# TOP_CTRL_TOP_CTRL register map
Vendor: Texas Instruments
Peripheral module from a debugger description file (folder AM263).
Registers are 32-bit, read-only, reset 0x0 unless marked. A register's access mark holds for its fields unless they carry their own. Offsets are as the file gives them; lines under a group give offsets from that group; [hi:lo] are bit positions; {n}, {i} and the like mark numbered series; 'fields as' and 'values as' point back to an identical list; <NAME> marks a mode.

## TOP_CTRL_TOP_CTRL
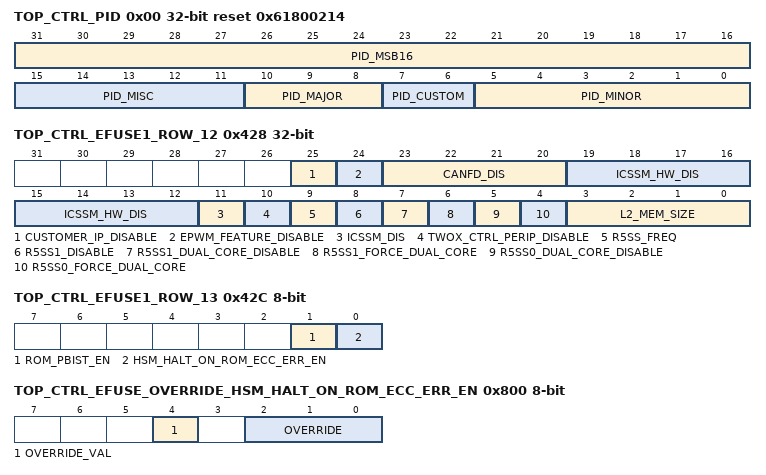
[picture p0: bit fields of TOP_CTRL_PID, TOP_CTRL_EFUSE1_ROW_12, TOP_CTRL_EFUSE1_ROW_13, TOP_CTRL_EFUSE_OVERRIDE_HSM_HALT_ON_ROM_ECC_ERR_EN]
0x00 TOP_CTRL_PID reset 0x61800214
  [31:16] PID_MSB16 — Not Defined
  [15:11] PID_MISC — Not Defined
  [10:8] PID_MAJOR — Not Defined
  [7:6] PID_CUSTOM — Not Defined
  [5:0] PID_MINOR — Not Defined
{0x10+4i} TOP_CTRL_EFUSE_DIEID{i} (i=0..3)
  [31:0] VAL — EFUSE DieID[{32i+31}:{32i}]
{0x20+4i} TOP_CTRL_EFUSE_UID{i} (i=0..2)
  [31:0] VAL — EFUSE UID[{32i+31}:{32i}]
0x2C TOP_CTRL_EFUSE_UID3 24-bit
  [23:0] VAL — EFUSE UID[120:96]
0x30 TOP_CTRL_EFUSE_DEVICE_TYPE 16-bit
  [15:0] VAL — EFUSE Device Type
0x34 TOP_CTRL_EFUSE_FROM0_CHECKSUM
  [31:0] VAL — 32 bit FROM0 Checksum
0x38 TOP_CTRL_EFUSE_JTAG_USERCODE_ID
  [31:0] VAL — EFUSE JTAG_USER_CODE_ID[31:0];. Denotes part variant
{0x30C+4i} TOP_CTRL_EFUSE0_ROW_{i} (i=61..63)
  [25:0] EFUSE0_ROW_{i} — Captures the EFUSE Value. Refer to EFUSE Mapping XLS for more details
{0x3F8+4i} TOP_CTRL_EFUSE1_ROW_{i} (i=5..11)
  [25:0] EFUSE1_ROW_{i} — Captures the EFUSE Value. Refer to EFUSE Mapping XLS for more details
0x428 TOP_CTRL_EFUSE1_ROW_12
  [25] CUSTOMER_IP_DISABLE — Customer IP set control0 - All IPs enabled1 - Customer IP set disabled (PWM24-31,CMPSSA6-9,CMPSSB6-9 disabled)
  [24] EPWM_FEATURE_DISABLE — Customer protected features inside PWM IP 0 - All features enabled1 - Customer defined features are protected
  [23:20] CANFD_DIS — CANFD disables. Bit positions correspond to CAN instance. 0 - CAN is enabled1 - CAN is disabled
  [19:12] ICSSM_HW_DIS — See ICSSM Spec for features
  [11] ICSSM_DIS — ICSSM IP disable0 - ICSSM enabled1 - ICSSM disabled
  [10] TWOX_CTRL_PERIP_DISABLE — 2x control IPs enabled0 - 1x control IPs (refer to PRD for the IP counts)1 - 2x control IPs (refer to PRD for the IP counts)
  [9] R5SS_FREQ — R5SS Freq0 - 400 MHz1 - 200 MHz
  [8] R5SS1_DISABLE — R5SS1 Disabled
  [7] R5SS1_DUAL_CORE_DISABLE — Force Lock step
  [6] R5SS1_FORCE_DUAL_CORE — Force Dual core
  [5] R5SS0_DUAL_CORE_DISABLE — Force Lock step
  [4] R5SS0_FORCE_DUAL_CORE — Force Dual core
  [3:0] L2_MEM_SIZE — Captures the EFUSE Value. Refer to EFUSE Mapping XLS for more details
0x42C TOP_CTRL_EFUSE1_ROW_13 8-bit
  [1] ROM_PBIST_EN — ROM PBIST ENABLE C ONTROL0 - PBIST DISABLE1 - PBIST ENABLE
  [0] HSM_HALT_ON_ROM_ECC_ERR_EN — Enabling halting of the HSM operation on a ROM ECC error that is detected.
{0x3F8+4i} TOP_CTRL_EFUSE1_ROW_{i} (i=14..56)
  fields as TOP_CTRL_EFUSE1_ROW_5
0x500 TOP_CTRL_MAC_ID0
  [31:0] MACID_LO — MAC ID low [32bits]
0x504 TOP_CTRL_MAC_ID1 16-bit
  [15:0] MACID_HI — MAC ID high [16bits]
0x510 TOP_CTRL_TRIM_TEMP_M40C 16-bit
  [10:0] TEMP — Record the temperature at which the temp sensor trims were performed
0x514 TOP_CTRL_TRIM_TEMPSENSE_M40C0
  [31:0] TRIM — Trim for temperature sensor calibration [Lower 32bits]
0x518 TOP_CTRL_TRIM_TEMPSENSE_M40C1 8-bit
  [8:0] TRIM — Trim for temperature sensor calibration [Upper 9bits]
0x51C TOP_CTRL_TRIM_TEMP_150C 16-bit
  fields as TOP_CTRL_TRIM_TEMP_M40C
0x520 TOP_CTRL_TRIM_TEMPSENSE_150C0
  [31:0] TRIM — Trim for temperature sensor calibration [Lower 32bits]
0x524 TOP_CTRL_TRIM_TEMPSENSE_150C1 8-bit
  [8:0] TRIM — Trim for temperature sensor calibration [Upper 9bits]
0x528 TOP_CTRL_TRIM_TEMP_30C 16-bit
  fields as TOP_CTRL_TRIM_TEMP_M40C
0x52C TOP_CTRL_TRIM_TEMPSENSE_30C0
  [31:0] TRIM — Trim for temperature sensor calibration [Lower 32bits]
0x530 TOP_CTRL_TRIM_TEMPSENSE_30C1 8-bit
  [8:0] TRIM — Trim for temperature sensor calibration [Upper 9bits]
0x534 TOP_CTRL_N_FACTOR_TEMPSENSE 16-bit
  [13:0] VAL — Temp Sensor N factor
0x538 TOP_CTRL_TSHUT_HOT 8-bit
  [7:0] VAL — Default efuse defined hot temperature shutdown. Can be overriden by writing to TSENSE0_TSHUT
0x53C TOP_CTRL_TSHUT_COLD 8-bit
  [7:0] VAL — Default efuse defined cold temperature shutdown. Can be overriden by writing to TSENSE0_TSHUT
0x800 TOP_CTRL_EFUSE_OVERRIDE_HSM_HALT_ON_ROM_ECC_ERR_EN 8-bit rw
  [4] OVERRIDE_VAL — Override MMR value
  [2:0] OVERRIDE — Override EFUSE Value with SW ValueWrite 3'b000 : EFUSE ValueWrite 3'b111 : MMR Value
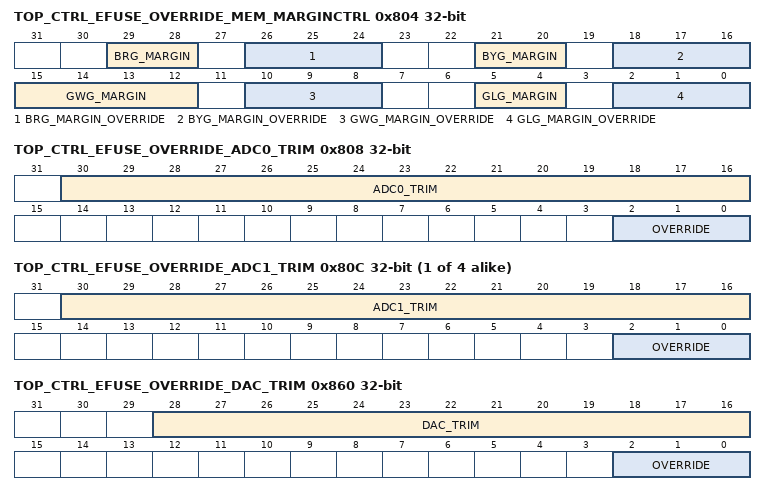
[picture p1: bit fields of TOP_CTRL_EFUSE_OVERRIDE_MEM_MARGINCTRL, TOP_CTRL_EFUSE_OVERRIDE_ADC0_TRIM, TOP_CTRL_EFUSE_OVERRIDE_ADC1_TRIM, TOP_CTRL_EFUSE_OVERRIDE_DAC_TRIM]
0x804 TOP_CTRL_EFUSE_OVERRIDE_MEM_MARGINCTRL rw
  [29:28] BRG_MARGIN — Override MMR value
  [26:24] BRG_MARGIN_OVERRIDE — Override EFUSE Value with SW ValueWrite 3'b000 : EFUSE ValueWrite 3'b111 : MMR Value
  [21:20] BYG_MARGIN — Override MMR value
  [18:16] BYG_MARGIN_OVERRIDE — Override EFUSE Value with SW ValueWrite 3'b000 : EFUSE ValueWrite 3'b111 : MMR Value
  [15:12] GWG_MARGIN — Override MMR value
  [10:8] GWG_MARGIN_OVERRIDE — Override EFUSE Value with SW ValueWrite 3'b000 : EFUSE ValueWrite 3'b111 : MMR Value
  [5:4] GLG_MARGIN — Override MMR value
  [2:0] GLG_MARGIN_OVERRIDE — Override EFUSE Value with SW ValueWrite 3'b000 : EFUSE ValueWrite 3'b111 : MMR Value
0x808 TOP_CTRL_EFUSE_OVERRIDE_ADC0_TRIM rw
  [30:16] ADC0_TRIM — offset trim of the ADC (3 values each 5 bit for SE-p, SE-m & Diff)
  [2:0] OVERRIDE — Override EFUSE Value with SW Value Write 3'b000 : EFUSE ValueWrite 3'b111 : MMR Value
{0x808+4i} TOP_CTRL_EFUSE_OVERRIDE_ADC{i}_TRIM rw (i=1..4)
  [30:16] ADC{i}_TRIM — offset trim of the ADC (3 values each 5 bit for SE-p, SE-m & Diff)
  [2:0] OVERRIDE — Override EFUSE Value with SW ValueWrite 3'b000 : EFUSE ValueWrite 3'b111 : MMR Value
0x81C TOP_CTRL_EFUSE_OVERRIDE_ADC_CFG_CTRL 8-bit rw
  [2:0] OVERRIDE — Override EFUSE Value with SW ValueWrite 3'b000 : EFUSE ValueWrite 3'b111 : MMR Value
0x820 TOP_CTRL_EFUSE_OVERRIDE_ADC_CFG0 rw reset 0x514554C9
  [31:0] ADC_CFG_31_0 — Family Trim. Will be same for all ADC's. Finalized during Bench/ATE char
0x824 TOP_CTRL_EFUSE_OVERRIDE_ADC_CFG1 rw reset 0x355688
  [31:0] ADC_CFG_63_32 — Family Trim. Will be same for all ADC's. Finalized during Bench/ATE char
0x828 TOP_CTRL_EFUSE_OVERRIDE_ADC_CFG2 24-bit rw reset 0x400001
  [23:0] ADC_CFG_87_64 — Family Trim. Will be same for all ADC's. Finalized during Bench/ATE char
0x82C TOP_CTRL_EFUSE_OVERRIDE_CSS01_TRIM_CTRL 8-bit rw
  fields as TOP_CTRL_EFUSE_OVERRIDE_ADC_CFG_CTRL
0x830 TOP_CTRL_EFUSE_OVERRIDE_CSS01_TRIM rw
  [31:0] CSS01_TRIM — CSS Trim signal
0x834 TOP_CTRL_EFUSE_OVERRIDE_CSS23_TRIM_CTRL 8-bit rw
  fields as TOP_CTRL_EFUSE_OVERRIDE_ADC_CFG_CTRL
0x838 TOP_CTRL_EFUSE_OVERRIDE_CSS23_TRIM rw
  [31:0] CSS23_TRIM — CSS Trim signal
0x83C TOP_CTRL_EFUSE_OVERRIDE_CSS45_TRIM_CTRL 8-bit rw
  fields as TOP_CTRL_EFUSE_OVERRIDE_ADC_CFG_CTRL
0x840 TOP_CTRL_EFUSE_OVERRIDE_CSS45_TRIM rw
  [31:0] CSS45_TRIM — CSS Trim signal
0x844 TOP_CTRL_EFUSE_OVERRIDE_CSS67_TRIM_CTRL 8-bit rw
  fields as TOP_CTRL_EFUSE_OVERRIDE_ADC_CFG_CTRL
0x848 TOP_CTRL_EFUSE_OVERRIDE_CSS67_TRIM rw
  [31:0] CSS67_TRIM — CSS Trim signal
0x84C TOP_CTRL_EFUSE_OVERRIDE_CSS89_TRIM_CTRL 8-bit rw
  fields as TOP_CTRL_EFUSE_OVERRIDE_ADC_CFG_CTRL
0x850 TOP_CTRL_EFUSE_OVERRIDE_CSS89_TRIM rw
  [31:0] CSS89_TRIM — CSS Trim signal
0x854 TOP_CTRL_EFUSE_OVERRIDE_CSS_CFG_CTRL 8-bit rw
  fields as TOP_CTRL_EFUSE_OVERRIDE_ADC_CFG_CTRL
0x858 TOP_CTRL_EFUSE_OVERRIDE_CSS_CFG0 rw
  [31:0] CSS_CFG_31_0 — Compdac Family trim (all CMPSS a & b)
0x85C TOP_CTRL_EFUSE_OVERRIDE_CSS_CFG1 rw
  [31:0] CSS_CFG_0_63_32 — Compdac Family trim (all CMPSS a & b)
0x860 TOP_CTRL_EFUSE_OVERRIDE_DAC_TRIM rw
  [28:16] DAC_TRIM — DAC Trim28:24 : [12:8] gain trim; 23:16 : [7:0] offset trim
  [2:0] OVERRIDE — Override EFUSE Value with SW ValueWrite 3'b000 : EFUSE ValueWrite 3'b111 : MMR Value
0x864 TOP_CTRL_EFUSE_OVERRIDE_DAC_CFG 24-bit rw
  [24] ASYNC_MODE_EN
  [17:16] IBIAS_CFG — ibias_cfg[1:0]
  [2:0] OVERRIDE — Override EFUSE Value with SW ValueWrite 3'b000 : EFUSE ValueWrite 3'b111 : MMR Value
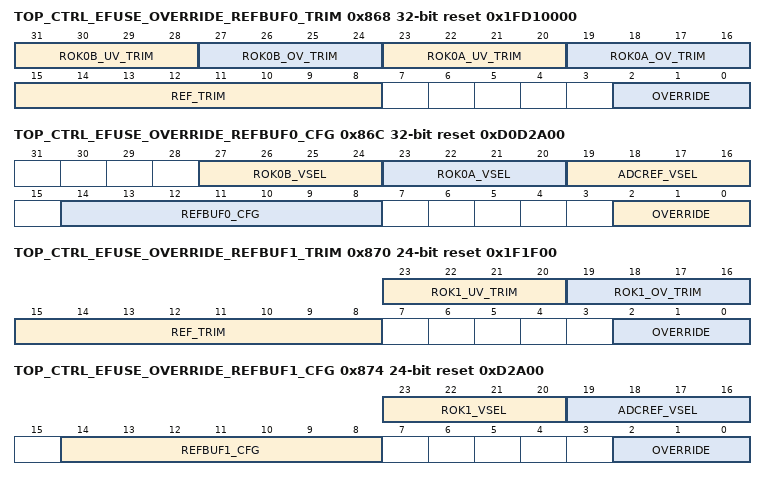
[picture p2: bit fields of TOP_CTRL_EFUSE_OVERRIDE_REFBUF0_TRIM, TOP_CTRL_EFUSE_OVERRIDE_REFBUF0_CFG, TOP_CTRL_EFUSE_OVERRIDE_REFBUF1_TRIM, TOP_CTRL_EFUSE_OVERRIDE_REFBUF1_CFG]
0x868 TOP_CTRL_EFUSE_OVERRIDE_REFBUF0_TRIM rw reset 0x1FD10000
  [31:28] ROK0B_UV_TRIM — ROK0B Under voltage threshold trim
  [27:24] ROK0B_OV_TRIM — ROK0B Over voltage threshold trim
  [23:20] ROK0A_UV_TRIM — ROK0A Under voltage threshold trim
  [19:16] ROK0A_OV_TRIM — ROK0A Over voltage threshold trim
  [15:8] REF_TRIM — Trims output voltage with 1mV steps, +/-30mV, default 0V
  [2:0] OVERRIDE — Override EFUSE Value with SW ValueWrite 3'b000 : EFUSE ValueWrite 3'b111 : MMR Value
0x86C TOP_CTRL_EFUSE_OVERRIDE_REFBUF0_CFG rw reset 0xD0D2A00
  [27:24] ROK0B_VSEL — Voltage selection for reference OK comp (1.46V to 1.86V) (ROK0B)
  [23:20] ROK0A_VSEL — Voltage selection for reference OK comp (1.46V to 1.86V)
  [19:16] ADCREF_VSEL — Selects output voltage level from 1.46V to 1.86V; default code is 1.8V
  [14:8] REFBUF0_CFG — Bit0: Debug feature, doubles the current of the 2nd stage. enfbres_pwdBit6-1: adjust current bias for the 1st, 2nd and 3rd stages.trim_ampbias[5:0]
  [2:0] OVERRIDE — Override EFUSE Value with SW ValueWrite 3'b000 : EFUSE ValueWrite 3'b111 : MMR Value
0x870 TOP_CTRL_EFUSE_OVERRIDE_REFBUF1_TRIM 24-bit rw reset 0x1F1F00
  [23:20] ROK1_UV_TRIM — ROK0A Under voltage threshold trim
  [19:16] ROK1_OV_TRIM — ROK0A Over voltage threshold trim
  [15:8] REF_TRIM — Trims output voltage with 1mV steps, +/-30mV, default 0V
  [2:0] OVERRIDE — Override EFUSE Value with SW ValueWrite 3'b000 : EFUSE ValueWrite 3'b111 : MMR Value
0x874 TOP_CTRL_EFUSE_OVERRIDE_REFBUF1_CFG 24-bit rw reset 0xD2A00
  [23:20] ROK1_VSEL — Voltage selection for reference OK comp (1.46V to 1.86V)
  [19:16] ADCREF_VSEL — Selects output voltage level from 1.46V to 1.86V; default code is 1.8V
  [14:8] REFBUF1_CFG — Bit0: Debug feature, doubles the current of the 2nd stage. enfbres_pwdBit6-1: adjust current bias for the 1st, 2nd and 3rd stages.trim_ampbias[5:0]
  [2:0] OVERRIDE — Override EFUSE Value with SW ValueWrite 3'b000 : EFUSE ValueWrite 3'b111 : MMR Value
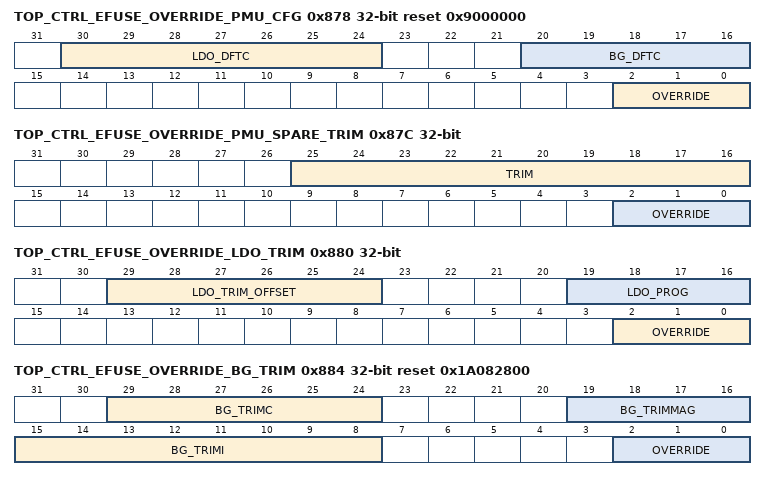
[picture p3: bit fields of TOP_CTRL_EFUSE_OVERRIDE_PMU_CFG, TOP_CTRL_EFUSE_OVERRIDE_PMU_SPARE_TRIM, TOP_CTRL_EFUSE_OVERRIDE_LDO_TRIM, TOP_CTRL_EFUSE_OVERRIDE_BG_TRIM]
0x878 TOP_CTRL_EFUSE_OVERRIDE_PMU_CFG rw reset 0x9000000
  [30:24] LDO_DFTC — Main LDO(1.8v) Config signals.Bit15: Not UsedBit14: 1 Double current in clampBit13: 1 Local ~200uA load resistor connected to ldooutBit12: 1 Amplifier ok bypassedBit 11-10: Adjust master current mirror in amplifier 2'b11 = 0.67x current 2'b10 = 0.5x current 2'b01 = 2.0x current 2'b00 = 1.0x currentBit9: 1 Allows higher slewing current (should only assert after bootup)
  [20:16] BG_DFTC — Bandgap DFT controls for debug purposes.Bit7: 1 To short large BJT base resistor to GNDBit6: 1 To short small BJT base resistor to GNDBit5: 1 To turn OFF startup pull NMOSBit4: 1 To turn OFF startup currentBit3: 1 to adjust(increase) BGAMP biasing
  [2:0] OVERRIDE — Override EFUSE Value with SW ValueWrite 3'b000 : EFUSE ValueWrite 3'b111 : MMR Value
0x87C TOP_CTRL_EFUSE_OVERRIDE_PMU_SPARE_TRIM rw
  [25:16] TRIM — PMU spare trim override value{pmu_trim_1p1v<7:6>,pmu_trim_1p1v<19:18>,pmu_trim_1p1v<35:30>}
  [2:0] OVERRIDE — Override EFUSE Value for PMU SPARE trimWrite 3'b000 : EFUSE ValueWrite 3'b111 : MMR Value
0x880 TOP_CTRL_EFUSE_OVERRIDE_LDO_TRIM rw
  [29:24] LDO_TRIM_OFFSET — LDO Fine trim around program point
  [19:16] LDO_PROG — LDO programming controls. Adjusts nominal LDO output voltage
  [2:0] OVERRIDE — Override EFUSE Value with SW ValueWrite 3'b000 : EFUSE ValueWrite 3'b111 : MMR Value
0x884 TOP_CTRL_EFUSE_OVERRIDE_BG_TRIM rw reset 0x1A082800
  [29:24] BG_TRIMC — Bandgap curvture/slope trim bits
  [19:16] BG_TRIMMAG — Bandgap magnitude trim bits
  [15:8] BG_TRIMI — [19:18] = Unused[17:12] = Bandgap current trim bits
  [2:0] OVERRIDE — Override EFUSE Value with SW ValueWrite 3'b000 : EFUSE ValueWrite 3'b111 : MMR Value
0x888 TOP_CTRL_EFUSE_OVERRIDE_SFTYMON_THRHLD_TRIM_CTRL 8-bit rw
  fields as TOP_CTRL_EFUSE_OVERRIDE_ADC_CFG_CTRL
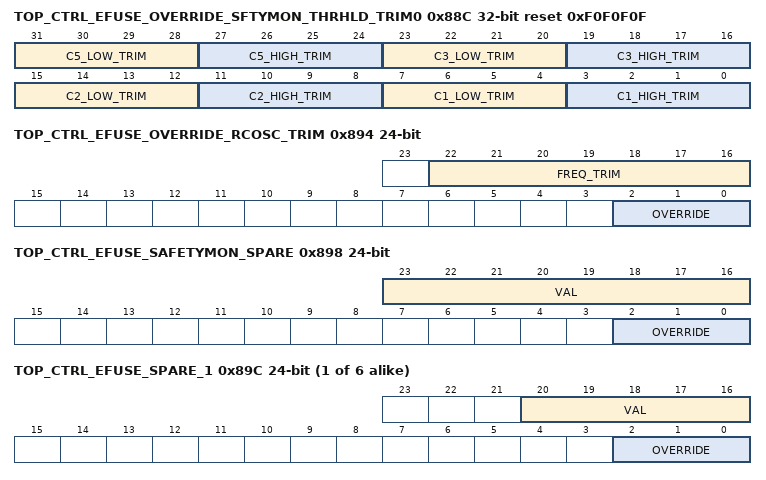
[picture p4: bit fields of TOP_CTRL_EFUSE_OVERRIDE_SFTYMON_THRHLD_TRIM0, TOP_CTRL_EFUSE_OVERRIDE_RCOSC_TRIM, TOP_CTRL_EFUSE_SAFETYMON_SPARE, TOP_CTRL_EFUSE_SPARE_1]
0x88C TOP_CTRL_EFUSE_OVERRIDE_SFTYMON_THRHLD_TRIM0 rw reset 0xF0F0F0F
  [31:28] C5_LOW_TRIM — C5, low side threshold trim setting
  [27:24] C5_HIGH_TRIM — C5, high side threshold trim setting
  [23:20] C3_LOW_TRIM — C3, low side threshold trim setting
  [19:16] C3_HIGH_TRIM — C3, high side threshold trim setting
  [15:12] C2_LOW_TRIM — C2, low side threshold trim setting
  [11:8] C2_HIGH_TRIM — C2, high side threshold trim setting
  [7:4] C1_LOW_TRIM — C1, low side threshold trim setting
  [3:0] C1_HIGH_TRIM — C1, high side threshold trim setting;
0x890 TOP_CTRL_EFUSE_OVERRIDE_SFTYMON_THRHLD_TRIM1 8-bit rw
  [3:0] C8_LOW_TRIM — C8, low side threshold trim setting
0x894 TOP_CTRL_EFUSE_OVERRIDE_RCOSC_TRIM 24-bit rw
  [22:16] FREQ_TRIM — RC oscillator frequency trim
  [2:0] OVERRIDE — Override EFUSE Value with SW ValueWrite 3'b000 : EFUSE ValueWrite 3'b111 : MMR Value
0x898 TOP_CTRL_EFUSE_SAFETYMON_SPARE 24-bit rw
  [23:16] VAL — SAFETYMON_SPARE trim override value
  [2:0] OVERRIDE — Override EFUSE Value with SW ValueWrite 3'b000 : EFUSE ValueWrite 3'b111 : MMR Value
{0x898+4i} TOP_CTRL_EFUSE_SPARE_{i} 24-bit rw (i=1..6)
  [20:16] VAL — SPARE_{i} trim override value
  [2:0] OVERRIDE — Override EFUSE Value with SW ValueWrite 3'b000 : EFUSE ValueWrite 3'b111 : MMR Value
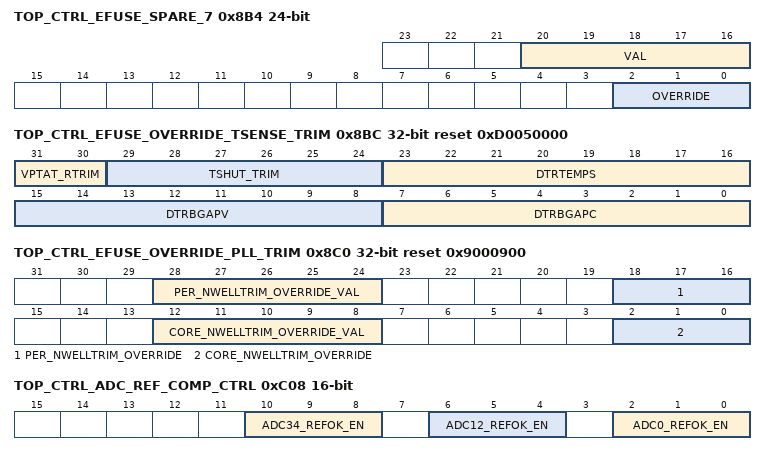
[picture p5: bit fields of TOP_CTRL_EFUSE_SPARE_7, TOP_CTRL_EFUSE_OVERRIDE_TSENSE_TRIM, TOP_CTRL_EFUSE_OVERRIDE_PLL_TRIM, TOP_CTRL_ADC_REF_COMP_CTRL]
0x8B4 TOP_CTRL_EFUSE_SPARE_7 24-bit rw
  [20:16] VAL — SPARE_6 trim override value
  [2:0] OVERRIDE — Override EFUSE Value with SW ValueWrite 3'b000 : EFUSE ValueWrite 3'b111 : MMR Value
0x8B8 TOP_CTRL_EFUSE_OVERRIDE_TSENSE_TRIM_CTRL 8-bit rw
  fields as TOP_CTRL_EFUSE_OVERRIDE_ADC_CFG_CTRL
0x8BC TOP_CTRL_EFUSE_OVERRIDE_TSENSE_TRIM rw reset 0xD0050000
  [31:30] VPTAT_RTRIM — TS: Vptat R trim (PTAT voltage resistor trim)
  [29:24] TSHUT_TRIM — Tshut Temperature C (Shutdown temperature trim)
  [23:16] DTRTEMPS — RDAC offset trim
  [15:8] DTRBGAPV — TS Bandgap magnitude trim
  [7:0] DTRBGAPC — TS Bandgap curvature trim
0x8C0 TOP_CTRL_EFUSE_OVERRIDE_PLL_TRIM rw reset 0x9000900
  [28:24] PER_NWELLTRIM_OVERRIDE_VAL — Peripheral ADPLL trim override value when per_adpll_trim_override is programmed
  [18:16] PER_NWELLTRIM_OVERRIDE — Peripheral ADPLL trim value is overridden by per_adpll_trim_override_val when this bit is programmed 1
  [12:8] CORE_NWELLTRIM_OVERRIDE_VAL — Core ADPLL trim override value when core_adpll_trim_override is programmed
  [2:0] CORE_NWELLTRIM_OVERRIDE — Core ADPLL trim value is overridden by core_adpll_trim_override_val when this bit is programmed 1
0xC00 TOP_CTRL_ADC_REFBUF0_CTRL 8-bit rw
  [2:0] ENABLE — Enables adc reference 0, mask hhv before enable000: Disable111 : Enable
0xC04 TOP_CTRL_ADC_REFBUF1_CTRL 8-bit rw
  fields as TOP_CTRL_ADC_REFBUF0_CTRL
0xC08 TOP_CTRL_ADC_REF_COMP_CTRL 16-bit rw
  [10:8] ADC34_REFOK_EN — enables reference comparators (ROK1). This monitors adc3 & adc4 refernc
  [6:4] ADC12_REFOK_EN — enables reference comparators (ROK0B). This monitors adc1 & adc2 refernce
  [2:0] ADC0_REFOK_EN — enables reference comparators (ROK0). This monitors adc0 refernce
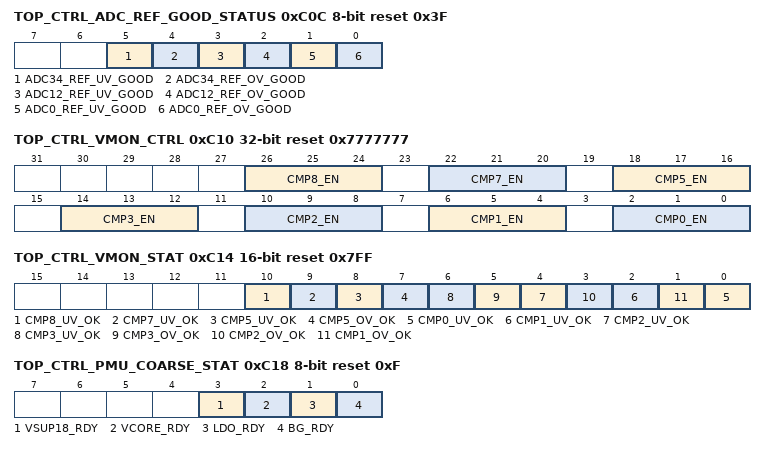
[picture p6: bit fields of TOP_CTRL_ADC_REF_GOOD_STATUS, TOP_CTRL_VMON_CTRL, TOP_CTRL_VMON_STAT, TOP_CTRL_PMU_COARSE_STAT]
0xC0C TOP_CTRL_ADC_REF_GOOD_STATUS 8-bit reset 0x3F
  [5] ADC34_REF_UV_GOOD — Under Voltage check OK
  [4] ADC34_REF_OV_GOOD — Over voltage check OK
  [3] ADC12_REF_UV_GOOD — Under Voltage check OK
  [2] ADC12_REF_OV_GOOD — Over voltage check OK
  [1] ADC0_REF_UV_GOOD — Under Voltage check OK
  [0] ADC0_REF_OV_GOOD — Over voltage check OK
0xC10 TOP_CTRL_VMON_CTRL rw reset 0x7777777
  [26:24] CMP8_EN — VMON EN
  [22:20] CMP7_EN — VMON EN
  [18:16] CMP5_EN — VMON EN
  [4n+2:4n] CMP{n}_EN (n=0..3) — VMON EN
0xC14 TOP_CTRL_VMON_STAT 16-bit reset 0x7FF
  [10] CMP8_UV_OK — VMON OK
  [9] CMP7_UV_OK — VMON OK
  [8] CMP5_UV_OK — VMON OK
  [7] CMP5_OV_OK — VMON OK
  [2n] CMP{n}_UV_OK (n=0..3) — VMON OK
  [5] CMP3_OV_OK — VMON OK
  [3] CMP2_OV_OK — VMON OK
  [1] CMP1_OV_OK — VMON OK
0xC18 TOP_CTRL_PMU_COARSE_STAT 8-bit reset 0xF
  [3] VSUP18_RDY — Coarse VMON OK
  [2] VCORE_RDY — Coarse VMON OK
  [1] LDO_RDY — Coarse VMON OK
  [0] BG_RDY — Coarse VMON OK
0xC20 TOP_CTRL_MASK_VMON_ERROR_ESM_H 16-bit rw reset 0x1FFFF
  [16] ADC34_REF_UV_MASK — VMON Error Mask to ESM
  [15] ADC34_REF_OV_MASK — VMON Error Mask to ESM
  [14] ADC12_REF_UV_MASK — VMON Error Mask to ESM
  [13] ADC12_REF_OV_MASK — VMON Error Mask to ESM
  [12] ADC0_REF_UV_MASK — VMON Error Mask to ESM
  [11] ADC0_REF_OV_MASK — VMON Error Mask to ESM
  [10] CMP8_UV_ERR_MASK — VMON Error Mask to ESM
  [9] CMP7_UV_ERR_MASK — VMON Error Mask to ESM
  [8] CMP5_UV_ERR_MASK — VMON Error Mask to ESM
  [7] CMP5_OV_ERR_MASK — VMON Error Mask to ESM
  [6] CMP3_UV_ERR_MASK — VMON Error Mask to ESM
  [5] CMP3_OV_ERR_MASK — VMON Error Mask to ESM
  [4] CMP2_UV_ERR_MASK — VMON Error Mask to ESM
  [3] CMP2_OV_ERR_MASK — VMON Error Mask to ESM
  [2] CMP1_UV_ERR_NASK — VMON Error Mask to ESM
  [1] CMP1_OV_ERR_MASK — VMON Error Mask to ESM
  [0] CMP0_UV_ERR_MASK — VMON Error Mask to ESM
0xC24 TOP_CTRL_MASK_VMON_ERROR_ESM_L 16-bit rw reset 0x1FFFF
  [16] ADC34_REF_UV_MASK — VMON Error Mask to INTR
  [15] ADC34_REF_OV_MASK — VMON Error Mask to INTR
  [14] ADC12_REF_UV_MASK — VMON Error Mask to INTR
  [13] ADC12_REF_OV_MASK — VMON Error Mask to INTR
  [12] ADC0_REF_UV_MASK — VMON Error Mask to INTR
  [11] ADC0_REF_OV_MASK — VMON Error Mask to INTR
  [10] CMP8_UV_ERR_MASK — VMON Error Mask to INTR
  [9] CMP7_UV_ERR_MASK — VMON Error Mask to INTR
  [8] CMP5_UV_ERR_MASK — VMON Error Mask to INTR
  [7] CMP5_OV_ERR_MASK — VMON Error Mask to INTR
  [6] CMP3_UV_ERR_MASK — VMON Error Mask to INTR
  [5] CMP3_OV_ERR_MASK — VMON Error Mask to INTR
  [4] CMP2_UV_ERR_MASK — VMON Error Mask to INTR
  [3] CMP2_OV_ERR_MASK — VMON Error Mask to INTR
  [2] CMP1_UV_ERR_NASK — VMON Error Mask to INTR
  [1] CMP1_OV_ERR_MASK — VMON Error Mask to INTR
  [0] CMP0_UV_ERR_MASK — VMON Error Mask to INTR
0xC30 TOP_CTRL_MASK_ANA_ISO 8-bit rw
  [2:0] MASK — Mask the Ana ISO generating SOC reset due to a glitch on VDD OK.Used during Trim updates to the analog or during ADC Refbuf enable
0xC34 TOP_CTRL_VMON_FILTER_CTRL 8-bit rw
  [1:0] SELECT_VALUE — VMON FILTER control select00 : no filtering (default)01 : filtering for 4.8us10 : filtering for 9.6us11 : filtering for 14.4us
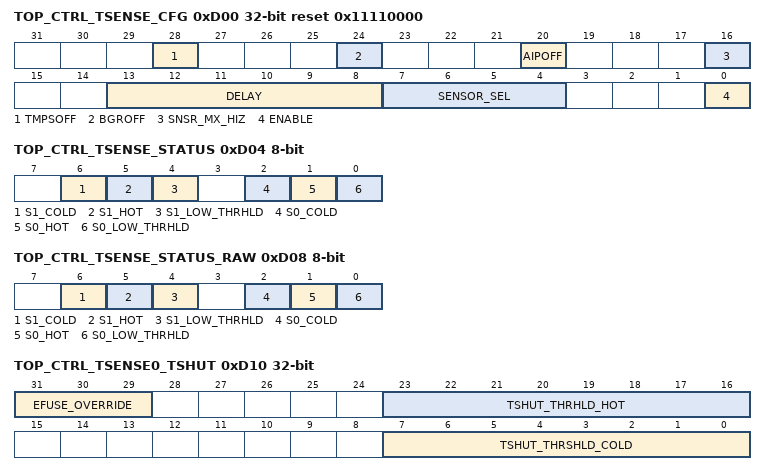
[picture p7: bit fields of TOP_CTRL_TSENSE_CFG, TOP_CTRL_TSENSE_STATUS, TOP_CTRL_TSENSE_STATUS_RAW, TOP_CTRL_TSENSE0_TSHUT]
0xD00 TOP_CTRL_TSENSE_CFG rw reset 0x11110000
  [28] TMPSOFF — Temperature sensor off0 : on1 : off
  [24] BGROFF — BandGap on/off control 1 : off 0 : on
  [20] AIPOFF — 1 : iddq mode select 0 : normal mode
  [16] SNSR_MX_HIZ — sensor mux hiz control0 : normal operation. Mux will select either one of the anlaog sensor 1 : mux will be high impedence
  [13:8] DELAY — number of wait clock cycles between each TMPS Readout. Configure a Non zero value as delay value since configuring 0 is not allowed
  [7:4] SENSOR_SEL — Sensor Selection sensor enable bits for each sensor 0 : sensor disable 1 : sensor enablebit 3: temp_sensor3bit 2: temp_sensor2bit 1: temp_sensor1bit 0: temp_sensor0
  [0] ENABLE — Temperature controller enable
0xD04 TOP_CTRL_TSENSE_STATUS 8-bit
  [6] S1_COLD — temperature Sensor 1 cold event detect0 : event not occured1 : event occurred
  [5] S1_HOT — temperature Sensor 1 hot event detect0 : event not occured1 : event occurred
  [4] S1_LOW_THRHLD — temperature Sensor 1 low threshold event detect0 : event not occured1 : event occurred
  [2] S0_COLD — temperature Sensor 0 cold event detect0 : event not occured1 : event occurred
  [1] S0_HOT — temperature Sensor 0 hot event detect0 : event not occured1 : event occurred
  [0] S0_LOW_THRHLD — temperature Sensor 0 low threshold event detect0 : event not occured1 : event occurred
0xD08 TOP_CTRL_TSENSE_STATUS_RAW 8-bit
  fields as TOP_CTRL_TSENSE_STATUS
0xD10 TOP_CTRL_TSENSE0_TSHUT rw
  [31:29] EFUSE_OVERRIDE — Efuse override000 -- Value from EFUSE is used as tshut hot and tshut cold thresholds111 - Overide value takes effect
  [23:16] TSHUT_THRHLD_HOT — tshut hot threshold. Reads efuse value untill overwritten with override = 111
  [7:0] TSHUT_THRSHLD_COLD — tshut cold threshold. Reads efuse value untill overwritten with override = 111
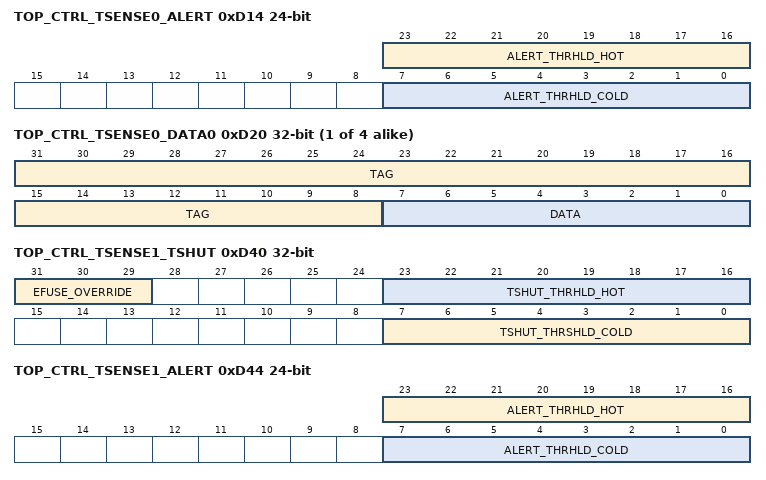
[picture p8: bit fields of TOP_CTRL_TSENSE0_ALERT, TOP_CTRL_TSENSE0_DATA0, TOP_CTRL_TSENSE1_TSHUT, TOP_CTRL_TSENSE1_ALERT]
0xD14 TOP_CTRL_TSENSE0_ALERT 24-bit rw
  [23:16] ALERT_THRHLD_HOT — hot threshold/high temp threshold
  [7:0] ALERT_THRHLD_COLD — cold threshold/low temp threshold
0xD18 TOP_CTRL_TSENSE0_CNTL 24-bit rw reset 0x100000
  [24] MASK_LOW_THRHLD — mask low threshold comparator output
  [20] MASK_COLD — mask cold comparator output
  [16] MASK_HOT — Mask hot comparator output
  [8] ACCU_CLEAR — accumulator clear
  [4] FIFO_FREEZE
  [0] FIFO_CLEAR
{0xD1C+0x30*i} TOP_CTRL_TSENSE{i}_RESULT 16-bit (i=0..3)
  [16] ECOZ — Conversion in Progress.1 : Conversion on going0 : conversion completed
  [7:0] DTEMP — Temp Code readout
{0xD20+4i} TOP_CTRL_TSENSE0_DATA{i} (i=0..3)
  [31:8] TAG — tag {i}
  [7:0] DATA — fifo data {i}
0xD30 TOP_CTRL_TSENSE0_ACCU
  [31:0] CUMUL — cumulative sum of past DTEMPs
0xD40 TOP_CTRL_TSENSE1_TSHUT rw
  fields as TOP_CTRL_TSENSE0_TSHUT
0xD44 TOP_CTRL_TSENSE1_ALERT 24-bit rw
  fields as TOP_CTRL_TSENSE0_ALERT
0xD48 TOP_CTRL_TSENSE1_CNTL 24-bit rw reset 0x100000
  fields as TOP_CTRL_TSENSE0_CNTL
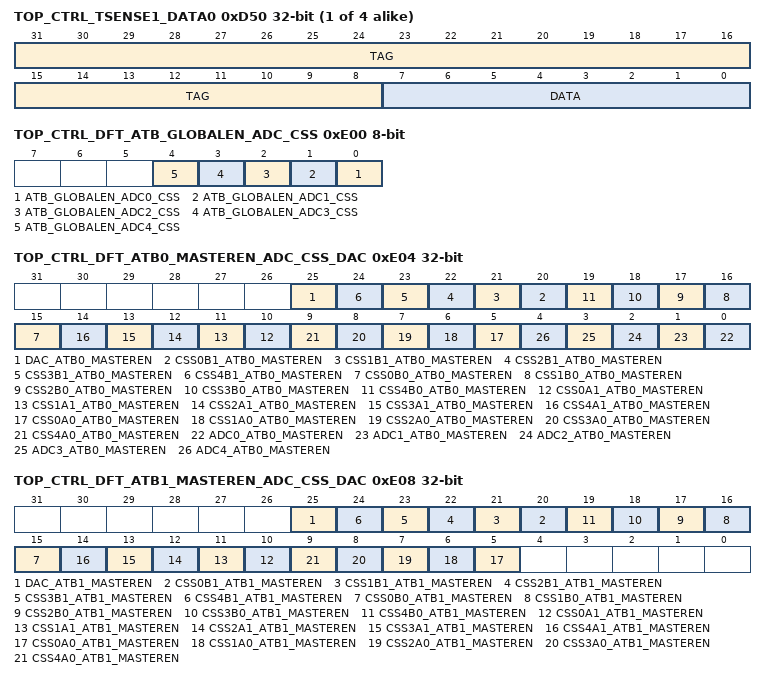
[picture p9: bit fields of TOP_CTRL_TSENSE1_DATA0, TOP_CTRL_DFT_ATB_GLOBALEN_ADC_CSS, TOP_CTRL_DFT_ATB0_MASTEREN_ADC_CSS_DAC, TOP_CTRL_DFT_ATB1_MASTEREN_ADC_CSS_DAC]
{0xD50+4i} TOP_CTRL_TSENSE1_DATA{i} (i=0..3)
  [31:8] TAG — tag {i}
  [7:0] DATA — fifo data {i}
0xD60 TOP_CTRL_TSENSE1_ACCU
  [31:0] CUMUL — cumulative sum of past DTEMPs
0xE00 TOP_CTRL_DFT_ATB_GLOBALEN_ADC_CSS 8-bit rw
  [n] ATB_GLOBALEN_ADC{n}_CSS (n=0..4) — ADC does not use 3V ATB This signal is used to enable master 3V & 1.8V switch (gates all cmpss 3V ATB access and cmpss+adc 1.8V atb access)
0xE04 TOP_CTRL_DFT_ATB0_MASTEREN_ADC_CSS_DAC rw
  [25] DAC_ATB0_MASTEREN — Master Enable : atb0 of dac12
  [n+20] CSS{n}B1_ATB0_MASTEREN (n=0..4) — Master Enable : atb0 of corresponding subsystems cmpss-b1
  [n+15] CSS{n}B0_ATB0_MASTEREN (n=0..4) — Master Enable : atb0 of corresponding subsystems cmpss-b0
  [n+10] CSS{n}A1_ATB0_MASTEREN (n=0..4) — Master Enable : atb0 of corresponding subsystems cmpss-a1
  [n+5] CSS{n}A0_ATB0_MASTEREN (n=0..4) — Master Enable : atb0 of corresponding subsystems cmpss-a0
  [n] ADC{n}_ATB0_MASTEREN (n=0..4) — Master Enable : atb0 of corresponding adc
0xE08 TOP_CTRL_DFT_ATB1_MASTEREN_ADC_CSS_DAC rw
  [25] DAC_ATB1_MASTEREN — Master Enable : atb0 of dac12
  [n+20] CSS{n}B1_ATB1_MASTEREN (n=0..4) — Master Enable : atb0 of corresponding subsystems cmpss-b1
  [n+15] CSS{n}B0_ATB1_MASTEREN (n=0..4) — Master Enable : atb0 of corresponding subsystems cmpss-b0
  [n+10] CSS{n}A1_ATB1_MASTEREN (n=0..4) — Master Enable : atb0 of corresponding subsystems cmpss-a1
  [n+5] CSS{n}A0_ATB1_MASTEREN (n=0..4) — Master Enable : atb0 of corresponding subsystems cmpss-a0
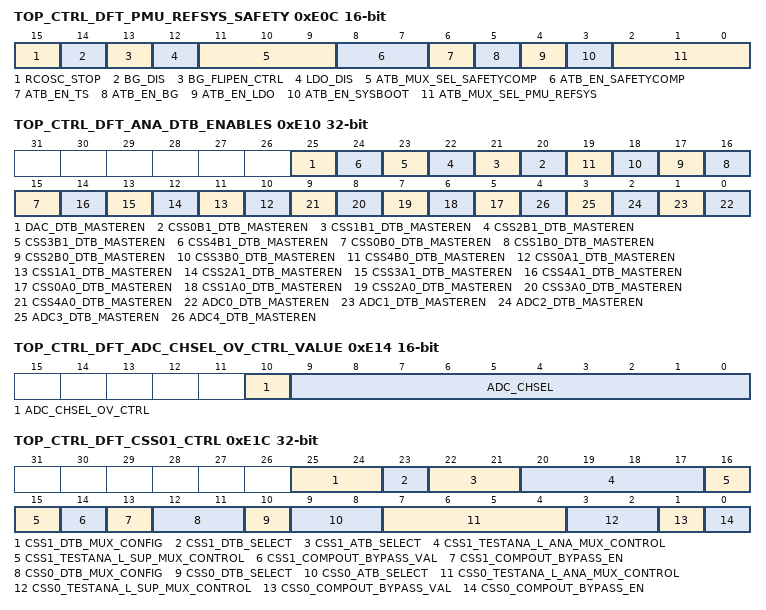
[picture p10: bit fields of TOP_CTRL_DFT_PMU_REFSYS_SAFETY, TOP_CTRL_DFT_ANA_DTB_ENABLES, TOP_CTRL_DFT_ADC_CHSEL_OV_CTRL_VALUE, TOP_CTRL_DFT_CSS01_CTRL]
0xE0C TOP_CTRL_DFT_PMU_REFSYS_SAFETY 16-bit rw
  [15] RCOSC_STOP — 0:rc enabled 1: stops rcosc clock
  [14] BG_DIS — Bandgap disable signal.1'b0 = Bandgap enabled. 1'b1 = Badgap disabled
  [13] BG_FLIPEN_CTRL — Bandgap flipen control for amplifier offset correction during trimming.1'b0 => normal operation; 1'b1 => AMP inputs flipped.
  [12] LDO_DIS — Disables LDO if set '1'
  [11:9] ATB_MUX_SEL_SAFETYCOMP — Selects analog signals for atestoutput for each of the test modes of the safety comparators according to test mode controlled by tb_ctrl_1p1v<83:82> : Test Mode 1 (tb_ctrl_1p1v<83:82>='b01): C5 & C20: HIZ 1: vssa of C5; 2:vth_lo of C5; 3: vth_hi of C5; 4:vssa of C2;5:vth_lo of C2; 6: vth_hi of C2; 7:HIZTest Mode 2 (tb_ctrl_1p1v<83:82>='b10): C3 & C80: HIZ 1: vssa of C3; 2:vth_lo of C3; 3: vth_hi of C3; 4:vssa of C8;5:vth_lo of C8; 6: vref of C8 (1.2V*0.5); 7:HIZTest Mode 3 (tb_ctrl_1p1v<83:82>='b11): C1 & C00: HIZ 1: vssa of C1; 2:vth_lo of C1; 3: vth_hi of C1; 4:vssa of C0;5:vmon of C0; 6: vref of C0 ; 7:HIZSelects Analog Test Signals for Temperature Sensor if tb_ctrl_1p1v<81> is enabled (refer to the spec for details).
  [8:7] ATB_EN_SAFETYCOMP — Enables three different test modes for safety comparators: 00: HIZ01: Test Mode1 enable10: Test Mode 2 enable11: Test Mode 3 enable
  [6] ATB_EN_TS — Analog test mode enable for temperature sesnsor
  [5] ATB_EN_BG — Bandgap atest enabled
  [4] ATB_EN_LDO — LDO atest enabled.
  [3] ATB_EN_SYSBOOT — atest enable pins for PMU. Only one bit should be high at a time.system boot logic atest enabled.
  [2:0] ATB_MUX_SEL_PMU_REFSYS — Common atest channel selection bits for bandgap, sysboot and LDO.Decoded to enable 8 channels of each module.
0xE10 TOP_CTRL_DFT_ANA_DTB_ENABLES rw
  [25] DAC_DTB_MASTEREN — Master Enable : dtb0 of dac12
  [n+20] CSS{n}B1_DTB_MASTEREN (n=0..4) — Master Enable : dtb0 of corresponding subsystems cmpss-b1
  [n+15] CSS{n}B0_DTB_MASTEREN (n=0..4) — Master Enable : dtb0 of corresponding subsystems cmpss-b0
  [n+10] CSS{n}A1_DTB_MASTEREN (n=0..4) — Master Enable : dtb0 of corresponding subsystems cmpss-a1
  [n+5] CSS{n}A0_DTB_MASTEREN (n=0..4) — Master Enable : dtb0 of corresponding subsystems cmpss-a0
  [n] ADC{n}_DTB_MASTEREN (n=0..4) — Master Enable : dtb0 of corresponding adc
0xE14 TOP_CTRL_DFT_ADC_CHSEL_OV_CTRL_VALUE 16-bit rw
  [10] ADC_CHSEL_OV_CTRL — 1 bit as the override control
  [9:0] ADC_CHSEL — ADC Channel select overrides adcX_ctrl_1p1v signal
0xE18 TOP_CTRL_DFT_DAC_CTRL 8-bit rw
  [8] DFT_LOAD_HIGH_EN — Connects 5k resistor between Vout and vdd_3p3v
  [7] DFT_LOAD_LOW_EN — Connects 5k resistor between Vout and VSS
  [6] IBIAS_20UA_ATB — connects ibias_20uA current sink to test bus
  [5] RDAC_VREF_HI_ATB — Connects RDAC VREF_HI to test bus
  [4] RDAC_VREF_LOW_ATB — Connects RDAC VREF_LOW to test bus
  [3] VSS_ATB — Connects VSS to test bus
  [2] VFEEDBACK_ATB — Connects Vfeedback node to test bus
  [1] RDAC_VBOT_ATB — Connects RDAC VBOT node to test bus
  [0] RDAC_VTOP_ATB — Connects RDAC VTOP node to test bus
0xE1C TOP_CTRL_DFT_CSS01_CTRL rw
  [25:24] CSS1_DTB_MUX_CONFIG — 2 b00 = MSB (default)2 b01 = LSB2 b10 = Enable2 b11 = compout
  [23] CSS1_DTB_SELECT — 1 b0 = dtb connected for compL (default)1 b1 = dtb connected for compH
  [22:21] CSS1_ATB_SELECT — 2 b00 = atb off (default)2 b01 = atb enable for compL2 b10 = atb enable for compH2 b11 = both ATB active
  [20:17] CSS1_TESTANA_L_ANA_MUX_CONTROL — 4 b0000 = 1p8v testana isolated (default)4 b0001 = vref_int4 b0010 = vref_low4 b0011 = vdac<0>4 b0100 = vdac<1>4 b0101 = vss4 b0110 = ibias 10uA ( atleast 1.25v at the pad)4 b0111 = por_ibias 10uA (atleast 1.25v at the pad)4 b1000 = cmp out1_p4 b1001 = cmp_out1_n
  [16:15] CSS1_TESTANA_L_SUP_MUX_CONTROL — For: compssa_L POS IN // NEG IN2 b00 = POS Mux control // DAC (default)2 b01 = ATB // DAC (tb_ctrl_1p1v<1> = 1'b1)2 b10 = POS Mux control // ATB (tb_ctrl_1p1v<1> = 1'b1)2 b11 = POS Mux control // DAC - ATB shorted (tb_ctrl_1p1v<1> = 1'b1)For: compssa_H POS IN // NEG IN2 b00 = inh // NEG Mux control (default)2 b01 = ATB (tb_ctrl_1p1v<1> = 1'b1) // NEG Mux control2 b10 = inh // ATB (tb_ctrl_1p1v<1> = 1'b1)2 b11 = inh // DAC - ATB shorted (tb_ctrl_1p1v<1> = 1'b1)
  [14] CSS1_COMPOUT_BYPASS_VAL — comparator bypass value
  [13] CSS1_COMPOUT_BYPASS_EN — 1 b0 = compout is connected to internal comparator (default)1 b1 = compout is equal to compout_bypass_val
  [12:11] CSS0_DTB_MUX_CONFIG — 2 b00 = MSB (default)2 b01 = LSB2 b10 = Enable2 b11 = compout
  [10] CSS0_DTB_SELECT — 1 b0 = dtb connected for compL (default)1 b1 = dtb connected for compH
  [9:8] CSS0_ATB_SELECT — 2 b00 = atb off (default)2 b01 = atb enable for compL2 b10 = atb enable for compH2 b11 = both ATB active
  [7:4] CSS0_TESTANA_L_ANA_MUX_CONTROL — 4 b0000 = 1p8v testana isolated (default)4 b0001 = vref_int4 b0010 = vref_low4 b0011 = vdac<0>4 b0100 = vdac<1>4 b0101 = vss4 b0110 = ibias 10uA ( atleast 1.25v at the pad)4 b0111 = por_ibias 10uA (atleast 1.25v at the pad)4 b1000 = cmp out1_p4 b1001 = cmp_out1_n
  [3:2] CSS0_TESTANA_L_SUP_MUX_CONTROL — For: compssa_L POS IN // NEG IN2 b00 = POS Mux control // DAC (default)2 b01 = ATB // DAC (tb_ctrl_1p1v<1> = 1'b1)2 b10 = POS Mux control // ATB (tb_ctrl_1p1v<1> = 1'b1)2 b11 = POS Mux control // DAC - ATB shorted (tb_ctrl_1p1v<1> = 1'b1)For: compssa_H POS IN // NEG IN2 b00 = inh // NEG Mux control (default)2 b01 = ATB (tb_ctrl_1p1v<1> = 1'b1) // NEG Mux control2 b10 = inh // ATB (tb_ctrl_1p1v<1> = 1'b1)2 b11 = inh // DAC - ATB shorted (tb_ctrl_1p1v<1> = 1'b1)
  [1] CSS0_COMPOUT_BYPASS_VAL — comparator bypass value
  [0] CSS0_COMPOUT_BYPASS_EN — 1 b0 = compout is connected to internal comparator (default)1 b1 = compout is equal to compout_bypass_val
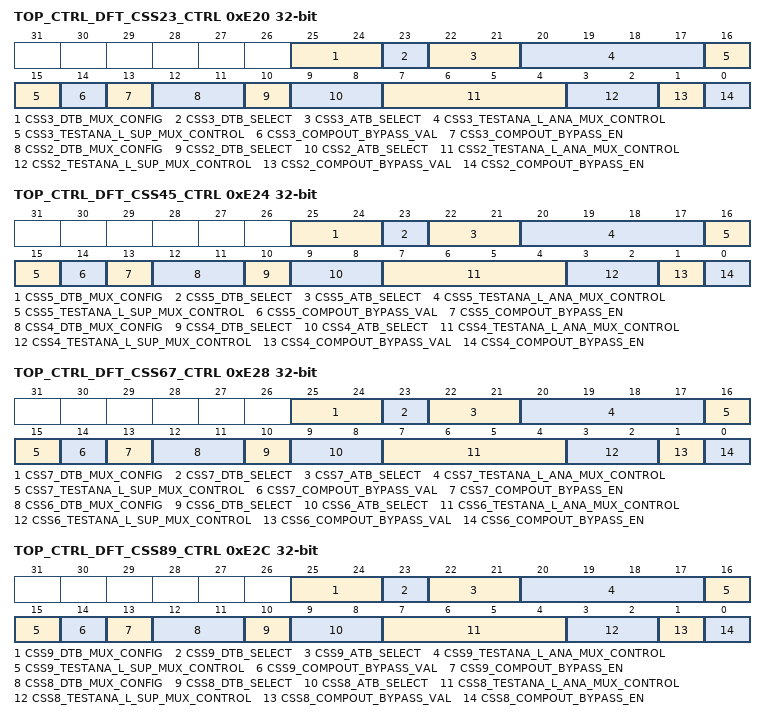
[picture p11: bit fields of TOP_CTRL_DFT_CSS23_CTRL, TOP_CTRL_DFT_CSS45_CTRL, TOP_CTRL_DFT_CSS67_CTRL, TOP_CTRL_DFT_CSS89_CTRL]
0xE20 TOP_CTRL_DFT_CSS23_CTRL rw
  [25:24] CSS3_DTB_MUX_CONFIG — 2 b00 = MSB (default)2 b01 = LSB2 b10 = Enable2 b11 = compout
  [23] CSS3_DTB_SELECT — 1 b0 = dtb connected for compL (default)1 b1 = dtb connected for compH
  [22:21] CSS3_ATB_SELECT — 2 b00 = atb off (default)2 b01 = atb enable for compL2 b10 = atb enable for compH2 b11 = both ATB active
  [20:17] CSS3_TESTANA_L_ANA_MUX_CONTROL — 4 b0000 = 1p8v testana isolated (default)4 b0001 = vref_int4 b0010 = vref_low4 b0011 = vdac<0>4 b0100 = vdac<1>4 b0101 = vss4 b0110 = ibias 10uA ( atleast 1.25v at the pad)4 b0111 = por_ibias 10uA (atleast 1.25v at the pad)4 b1000 = cmp out1_p4 b1001 = cmp_out1_n
  [16:15] CSS3_TESTANA_L_SUP_MUX_CONTROL — For: compssa_L POS IN // NEG IN2 b00 = POS Mux control // DAC (default)2 b01 = ATB // DAC (tb_ctrl_1p1v<1> = 1'b1)2 b10 = POS Mux control // ATB (tb_ctrl_1p1v<1> = 1'b1)2 b11 = POS Mux control // DAC - ATB shorted (tb_ctrl_1p1v<1> = 1'b1)For: compssa_H POS IN // NEG IN2 b00 = inh // NEG Mux control (default)2 b01 = ATB (tb_ctrl_1p1v<1> = 1'b1) // NEG Mux control2 b10 = inh // ATB (tb_ctrl_1p1v<1> = 1'b1)2 b11 = inh // DAC - ATB shorted (tb_ctrl_1p1v<1> = 1'b1)
  [14] CSS3_COMPOUT_BYPASS_VAL — comparator bypass value
  [13] CSS3_COMPOUT_BYPASS_EN — 1 b0 = compout is connected to internal comparator (default)1 b1 = compout is equal to compout_bypass_val
  [12:11] CSS2_DTB_MUX_CONFIG — 2 b00 = MSB (default)2 b01 = LSB2 b10 = Enable2 b11 = compout
  [10] CSS2_DTB_SELECT — 1 b0 = dtb connected for compL (default)1 b1 = dtb connected for compH
  [9:8] CSS2_ATB_SELECT — 2 b00 = atb off (default)2 b01 = atb enable for compL2 b10 = atb enable for compH2 b11 = both ATB active
  [7:4] CSS2_TESTANA_L_ANA_MUX_CONTROL — 4 b0000 = 1p8v testana isolated (default)4 b0001 = vref_int4 b0010 = vref_low4 b0011 = vdac<0>4 b0100 = vdac<1>4 b0101 = vss4 b0110 = ibias 10uA ( atleast 1.25v at the pad)4 b0111 = por_ibias 10uA (atleast 1.25v at the pad)4 b1000 = cmp out1_p4 b1001 = cmp_out1_n
  [3:2] CSS2_TESTANA_L_SUP_MUX_CONTROL — For: compssa_L POS IN // NEG IN2 b00 = POS Mux control // DAC (default)2 b01 = ATB // DAC (tb_ctrl_1p1v<1> = 1'b1)2 b10 = POS Mux control // ATB (tb_ctrl_1p1v<1> = 1'b1)2 b11 = POS Mux control // DAC - ATB shorted (tb_ctrl_1p1v<1> = 1'b1)For: compssa_H POS IN // NEG IN2 b00 = inh // NEG Mux control (default)2 b01 = ATB (tb_ctrl_1p1v<1> = 1'b1) // NEG Mux control2 b10 = inh // ATB (tb_ctrl_1p1v<1> = 1'b1)2 b11 = inh // DAC - ATB shorted (tb_ctrl_1p1v<1> = 1'b1)
  [1] CSS2_COMPOUT_BYPASS_VAL — comparator bypass value
  [0] CSS2_COMPOUT_BYPASS_EN — 1 b0 = compout is connected to internal comparator (default)1 b1 = compout is equal to compout_bypass_val
0xE24 TOP_CTRL_DFT_CSS45_CTRL rw
  [25:24] CSS5_DTB_MUX_CONFIG — 2 b00 = MSB (default)2 b01 = LSB2 b10 = Enable2 b11 = compout
  [23] CSS5_DTB_SELECT — 1 b0 = dtb connected for compL (default)1 b1 = dtb connected for compH
  [22:21] CSS5_ATB_SELECT — 2 b00 = atb off (default)2 b01 = atb enable for compL2 b10 = atb enable for compH2 b11 = both ATB active
  [20:17] CSS5_TESTANA_L_ANA_MUX_CONTROL — 4 b0000 = 1p8v testana isolated (default)4 b0001 = vref_int4 b0010 = vref_low4 b0011 = vdac<0>4 b0100 = vdac<1>4 b0101 = vss4 b0110 = ibias 10uA ( atleast 1.25v at the pad)4 b0111 = por_ibias 10uA (atleast 1.25v at the pad)4 b1000 = cmp out1_p4 b1001 = cmp_out1_n
  [16:15] CSS5_TESTANA_L_SUP_MUX_CONTROL — For: compssa_L POS IN // NEG IN2 b00 = POS Mux control // DAC (default)2 b01 = ATB // DAC (tb_ctrl_1p1v<1> = 1'b1)2 b10 = POS Mux control // ATB (tb_ctrl_1p1v<1> = 1'b1)2 b11 = POS Mux control // DAC - ATB shorted (tb_ctrl_1p1v<1> = 1'b1)For: compssa_H POS IN // NEG IN2 b00 = inh // NEG Mux control (default)2 b01 = ATB (tb_ctrl_1p1v<1> = 1'b1) // NEG Mux control2 b10 = inh // ATB (tb_ctrl_1p1v<1> = 1'b1)2 b11 = inh // DAC - ATB shorted (tb_ctrl_1p1v<1> = 1'b1)
  [14] CSS5_COMPOUT_BYPASS_VAL — comparator bypass value
  [13] CSS5_COMPOUT_BYPASS_EN — 1 b0 = compout is connected to internal comparator (default)1 b1 = compout is equal to compout_bypass_val
  [12:11] CSS4_DTB_MUX_CONFIG — 2 b00 = MSB (default)2 b01 = LSB2 b10 = Enable2 b11 = compout
  [10] CSS4_DTB_SELECT — 1 b0 = dtb connected for compL (default)1 b1 = dtb connected for compH
  [9:8] CSS4_ATB_SELECT — 2 b00 = atb off (default)2 b01 = atb enable for compL2 b10 = atb enable for compH2 b11 = both ATB active
  [7:4] CSS4_TESTANA_L_ANA_MUX_CONTROL — 4 b0000 = 1p8v testana isolated (default)4 b0001 = vref_int4 b0010 = vref_low4 b0011 = vdac<0>4 b0100 = vdac<1>4 b0101 = vss4 b0110 = ibias 10uA ( atleast 1.25v at the pad)4 b0111 = por_ibias 10uA (atleast 1.25v at the pad)4 b1000 = cmp out1_p4 b1001 = cmp_out1_n
  [3:2] CSS4_TESTANA_L_SUP_MUX_CONTROL — For: compssa_L POS IN // NEG IN2 b00 = POS Mux control // DAC (default)2 b01 = ATB // DAC (tb_ctrl_1p1v<1> = 1'b1)2 b10 = POS Mux control // ATB (tb_ctrl_1p1v<1> = 1'b1)2 b11 = POS Mux control // DAC - ATB shorted (tb_ctrl_1p1v<1> = 1'b1)For: compssa_H POS IN // NEG IN2 b00 = inh // NEG Mux control (default)2 b01 = ATB (tb_ctrl_1p1v<1> = 1'b1) // NEG Mux control2 b10 = inh // ATB (tb_ctrl_1p1v<1> = 1'b1)2 b11 = inh // DAC - ATB shorted (tb_ctrl_1p1v<1> = 1'b1)
  [1] CSS4_COMPOUT_BYPASS_VAL — comparator bypass value
  [0] CSS4_COMPOUT_BYPASS_EN — 1 b0 = compout is connected to internal comparator (default)1 b1 = compout is equal to compout_bypass_val
0xE28 TOP_CTRL_DFT_CSS67_CTRL rw
  [25:24] CSS7_DTB_MUX_CONFIG — 2 b00 = MSB (default)2 b01 = LSB2 b10 = Enable2 b11 = compout
  [23] CSS7_DTB_SELECT — 1 b0 = dtb connected for compL (default)1 b1 = dtb connected for compH
  [22:21] CSS7_ATB_SELECT — 2 b00 = atb off (default)2 b01 = atb enable for compL2 b10 = atb enable for compH2 b11 = both ATB active
  [20:17] CSS7_TESTANA_L_ANA_MUX_CONTROL — 4 b0000 = 1p8v testana isolated (default)4 b0001 = vref_int4 b0010 = vref_low4 b0011 = vdac<0>4 b0100 = vdac<1>4 b0101 = vss4 b0110 = ibias 10uA ( atleast 1.25v at the pad)4 b0111 = por_ibias 10uA (atleast 1.25v at the pad)4 b1000 = cmp out1_p4 b1001 = cmp_out1_n
  [16:15] CSS7_TESTANA_L_SUP_MUX_CONTROL — For: compssa_L POS IN // NEG IN2 b00 = POS Mux control // DAC (default)2 b01 = ATB // DAC (tb_ctrl_1p1v<1> = 1'b1)2 b10 = POS Mux control // ATB (tb_ctrl_1p1v<1> = 1'b1)2 b11 = POS Mux control // DAC - ATB shorted (tb_ctrl_1p1v<1> = 1'b1)For: compssa_H POS IN // NEG IN2 b00 = inh // NEG Mux control (default)2 b01 = ATB (tb_ctrl_1p1v<1> = 1'b1) // NEG Mux control2 b10 = inh // ATB (tb_ctrl_1p1v<1> = 1'b1)2 b11 = inh // DAC - ATB shorted (tb_ctrl_1p1v<1> = 1'b1)
  [14] CSS7_COMPOUT_BYPASS_VAL — comparator bypass value
  [13] CSS7_COMPOUT_BYPASS_EN — 1 b0 = compout is connected to internal comparator (default)1 b1 = compout is equal to compout_bypass_val
  [12:11] CSS6_DTB_MUX_CONFIG — 2 b00 = MSB (default)2 b01 = LSB2 b10 = Enable2 b11 = compout
  [10] CSS6_DTB_SELECT — 1 b0 = dtb connected for compL (default)1 b1 = dtb connected for compH
  [9:8] CSS6_ATB_SELECT — 2 b00 = atb off (default)2 b01 = atb enable for compL2 b10 = atb enable for compH2 b11 = both ATB active
  [7:4] CSS6_TESTANA_L_ANA_MUX_CONTROL — 4 b0000 = 1p8v testana isolated (default)4 b0001 = vref_int4 b0010 = vref_low4 b0011 = vdac<0>4 b0100 = vdac<1>4 b0101 = vss4 b0110 = ibias 10uA ( atleast 1.25v at the pad)4 b0111 = por_ibias 10uA (atleast 1.25v at the pad)4 b1000 = cmp out1_p4 b1001 = cmp_out1_n
  [3:2] CSS6_TESTANA_L_SUP_MUX_CONTROL — For: compssa_L POS IN // NEG IN2 b00 = POS Mux control // DAC (default)2 b01 = ATB // DAC (tb_ctrl_1p1v<1> = 1'b1)2 b10 = POS Mux control // ATB (tb_ctrl_1p1v<1> = 1'b1)2 b11 = POS Mux control // DAC - ATB shorted (tb_ctrl_1p1v<1> = 1'b1)For: compssa_H POS IN // NEG IN2 b00 = inh // NEG Mux control (default)2 b01 = ATB (tb_ctrl_1p1v<1> = 1'b1) // NEG Mux control2 b10 = inh // ATB (tb_ctrl_1p1v<1> = 1'b1)2 b11 = inh // DAC - ATB shorted (tb_ctrl_1p1v<1> = 1'b1)
  [1] CSS6_COMPOUT_BYPASS_VAL — comparator bypass value
  [0] CSS6_COMPOUT_BYPASS_EN — 1 b0 = compout is connected to internal comparator (default)1 b1 = compout is equal to compout_bypass_val
0xE2C TOP_CTRL_DFT_CSS89_CTRL rw
  [25:24] CSS9_DTB_MUX_CONFIG — 2 b00 = MSB (default)2 b01 = LSB2 b10 = Enable2 b11 = compout
  [23] CSS9_DTB_SELECT — 1 b0 = dtb connected for compL (default)1 b1 = dtb connected for compH
  [22:21] CSS9_ATB_SELECT — 2 b00 = atb off (default)2 b01 = atb enable for compL2 b10 = atb enable for compH2 b11 = both ATB active
  [20:17] CSS9_TESTANA_L_ANA_MUX_CONTROL — 4 b0000 = 1p8v testana isolated (default)4 b0001 = vref_int4 b0010 = vref_low4 b0011 = vdac<0>4 b0100 = vdac<1>4 b0101 = vss4 b0110 = ibias 10uA ( atleast 1.25v at the pad)4 b0111 = por_ibias 10uA (atleast 1.25v at the pad)4 b1000 = cmp out1_p4 b1001 = cmp_out1_n
  [16:15] CSS9_TESTANA_L_SUP_MUX_CONTROL — For: compssa_L POS IN // NEG IN2 b00 = POS Mux control // DAC (default)2 b01 = ATB // DAC (tb_ctrl_1p1v<1> = 1'b1)2 b10 = POS Mux control // ATB (tb_ctrl_1p1v<1> = 1'b1)2 b11 = POS Mux control // DAC - ATB shorted (tb_ctrl_1p1v<1> = 1'b1)For: compssa_H POS IN // NEG IN2 b00 = inh // NEG Mux control (default)2 b01 = ATB (tb_ctrl_1p1v<1> = 1'b1) // NEG Mux control2 b10 = inh // ATB (tb_ctrl_1p1v<1> = 1'b1)2 b11 = inh // DAC - ATB shorted (tb_ctrl_1p1v<1> = 1'b1)
  [14] CSS9_COMPOUT_BYPASS_VAL — comparator bypass value
  [13] CSS9_COMPOUT_BYPASS_EN — 1 b0 = compout is connected to internal comparator (default)1 b1 = compout is equal to compout_bypass_val
  [12:11] CSS8_DTB_MUX_CONFIG — 2 b00 = MSB (default)2 b01 = LSB2 b10 = Enable2 b11 = compout
  [10] CSS8_DTB_SELECT — 1 b0 = dtb connected for compL (default)1 b1 = dtb connected for compH
  [9:8] CSS8_ATB_SELECT — 2 b00 = atb off (default)2 b01 = atb enable for compL2 b10 = atb enable for compH2 b11 = both ATB active
  [7:4] CSS8_TESTANA_L_ANA_MUX_CONTROL — 4 b0000 = 1p8v testana isolated (default)4 b0001 = vref_int4 b0010 = vref_low4 b0011 = vdac<0>4 b0100 = vdac<1>4 b0101 = vss4 b0110 = ibias 10uA ( atleast 1.25v at the pad)4 b0111 = por_ibias 10uA (atleast 1.25v at the pad)4 b1000 = cmp out1_p4 b1001 = cmp_out1_n
  [3:2] CSS8_TESTANA_L_SUP_MUX_CONTROL — For: compssa_L POS IN // NEG IN2 b00 = POS Mux control // DAC (default)2 b01 = ATB // DAC (tb_ctrl_1p1v<1> = 1'b1)2 b10 = POS Mux control // ATB (tb_ctrl_1p1v<1> = 1'b1)2 b11 = POS Mux control // DAC - ATB shorted (tb_ctrl_1p1v<1> = 1'b1)For: compssa_H POS IN // NEG IN2 b00 = inh // NEG Mux control (default)2 b01 = ATB (tb_ctrl_1p1v<1> = 1'b1) // NEG Mux control2 b10 = inh // ATB (tb_ctrl_1p1v<1> = 1'b1)2 b11 = inh // DAC - ATB shorted (tb_ctrl_1p1v<1> = 1'b1)
  [1] CSS8_COMPOUT_BYPASS_VAL — comparator bypass value
  [0] CSS8_COMPOUT_BYPASS_EN — 1 b0 = compout is connected to internal comparator (default)1 b1 = compout is equal to compout_bypass_val
0xE30 TOP_CTRL_DFT_RAMP_DACL 24-bit rw
  [19:0] RAMP_DACL — Fanout internal ramp to DACL of the CMPSS (currently reserved)
0xE34 TOP_CTRL_DFT_REFBUF_CTRL 8-bit rw
  [8:7] REFBUF1_ATB_MUX_SEL — Analog test select controls for reference buffer and comparators
  [6:5] REFBUF0_ATB_MUX_SEL — Analog test select controls for reference buffer and comparators
  [4] REFBUF1_ATBEN — Atest enable REFBUF1
  [3] REFBUF1_ATBEN_ROK1 — analog test enable for the comparators ROK1
  [2] REFBUF0_ATBEN — Atest enable REFBUF0
  [1] REFBUF0_ATBEN_ROK0 — analog test enable for the comparators ROK0
  [0] REFBUF0_ATBEN_ROK0B — analog test enable for the comparators ROK0B
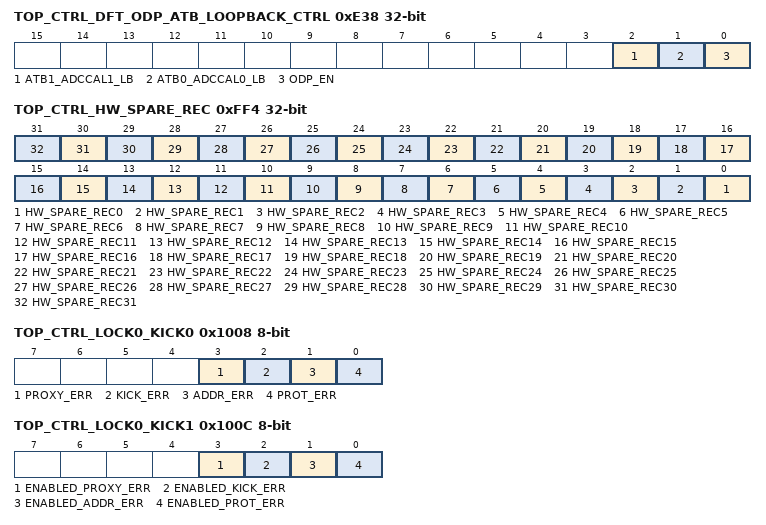
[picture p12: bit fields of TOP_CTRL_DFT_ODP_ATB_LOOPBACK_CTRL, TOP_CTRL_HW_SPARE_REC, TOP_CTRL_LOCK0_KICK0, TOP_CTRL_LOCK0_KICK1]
0xE38 TOP_CTRL_DFT_ODP_ATB_LOOPBACK_CTRL rw
  [2] ATB1_ADCCAL1_LB — if '1' connects atestv1 to adc_cal1
  [1] ATB0_ADCCAL0_LB — if '1' connects atestv0 to adc_cal0 (must ensure adc_cal0 is not driven)
  [0] ODP_EN — must set '1' to test odp module
0xE3C TOP_CTRL_DFT_SOC_DTB_MUX_SEL 8-bit rw
  [7:0] DTB_MUX_SEL — Mux selection controls for selecting the DTB lines going out of SOC for debug purpose and for testing.
0xE40 TOP_CTRL_DFT_TEMPSENSE_CTRL size not given rw
  [0] SENSOR5_SEL — Sensor control for 5th local sensor
{0xE40+4i} TOP_CTRL_DFT_CTRL_{i} rw (i=1..4)
0xF04 TOP_CTRL_PROBE_BUS_SEL0 rw
  [31:0] SEL — Probe Bus 0 Mux Select
0xF08 TOP_CTRL_PROBE_BUS_SEL1 rw
  [31:0] SEL — Probe Bus 1 Mux Select
{0xFD0+4i} TOP_CTRL_HW_SPARE_RW{i} rw (i=0..3)
  [31:0] HW_SPARE_RW{i} — Reserved for HW R&D
{0xFE0+4i} TOP_CTRL_HW_SPARE_RO{i} (i=0..3)
  [31:0] HW_SPARE_RO{i} — Reserved for HW R&D
0xFF0 TOP_CTRL_HW_SPARE_WPH rw
  [31:0] HW_SPARE_WPH — Reserved for HW R&D
0xFF4 TOP_CTRL_HW_SPARE_REC rw
  [n] HW_SPARE_REC{n} (n=0..31) — Reserved for HW R&D
0xFF8 TOP_CTRL_HW_SPARE_REC0 rw
  [31:0] LOCK0_KICK0 — - KICK0 component
0xFFC TOP_CTRL_HW_SPARE_REC1 rw
  [31:0] LOCK0_KICK1 — - KICK1 component
0x1008 TOP_CTRL_LOCK0_KICK0 8-bit rw
  [3] PROXY_ERR — Proxy0 access violation error. Raw status is read. Write a 1 to set the status. Writing a 0 has no effect.
  [2] KICK_ERR — Kick access violation error. Raw status is read. Write a 1 to set the status. Writing a 0 has no effect.
  [1] ADDR_ERR — Addressing violation error. Raw status is read. Write a 1 to set the status. Writing a 0 has no effect.
  [0] PROT_ERR — Protection violation error. Raw status is read. Write a 1 to set the status. Writing a 0 has no effect.
0x100C TOP_CTRL_LOCK0_KICK1 8-bit rw
  [3] ENABLED_PROXY_ERR — Proxy0 access violation error. Enabled status is read. Write a 1 to clear the status. Writing a 0 has no effect.
  [2] ENABLED_KICK_ERR — Kick access violation error. Enabled status is read. Write a 1 to clear the status. Writing a 0 has no effect.
  [1] ENABLED_ADDR_ERR — Addressing violation error. Enabled status is read. Write a 1 to clear the status. Writing a 0 has no effect.
  [0] ENABLED_PROT_ERR — Protection violation error. Enabled status is read. Write a 1 to clear the status. Writing a 0 has no effect.
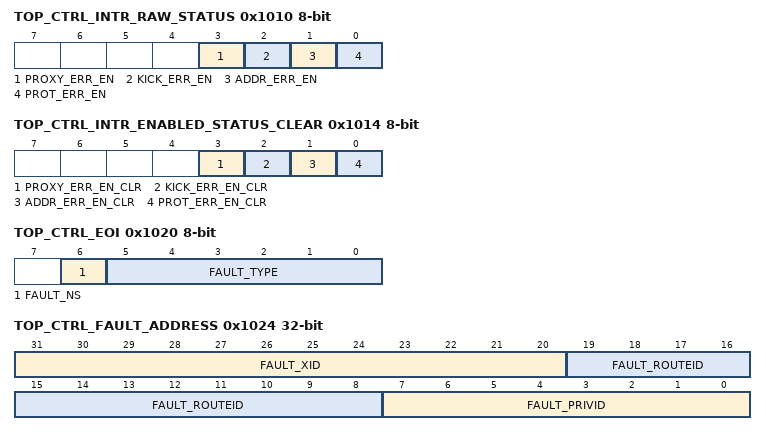
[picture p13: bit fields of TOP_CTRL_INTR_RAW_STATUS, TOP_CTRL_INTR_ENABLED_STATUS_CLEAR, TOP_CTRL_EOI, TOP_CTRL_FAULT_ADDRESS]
0x1010 TOP_CTRL_INTR_RAW_STATUS 8-bit rw
  [3] PROXY_ERR_EN — Proxy0 access violation error enable. Write a 1 to set the enable. Writing a 0 has no effect.
  [2] KICK_ERR_EN — Kick access violation error enable. Write a 1 to set the enable. Writing a 0 has no effect.
  [1] ADDR_ERR_EN — Addressing violation error enable. Write a 1 to set the enable. Writing a 0 has no effect.
  [0] PROT_ERR_EN — Protection violation error enable. Write a 1 to set the enable. Writing a 0 has no effect.
0x1014 TOP_CTRL_INTR_ENABLED_STATUS_CLEAR 8-bit rw
  [3] PROXY_ERR_EN_CLR — Proxy0 access violation error enable clear. Write a 1 to clear the enable. Writing a 0 has no effect.
  [2] KICK_ERR_EN_CLR — Kick access violation error enable clear. Write a 1 to clear the enable. Writing a 0 has no effect.
  [1] ADDR_ERR_EN_CLR — Addressing violation error enable clear. Write a 1 to clear the enable. Writing a 0 has no effect.
  [0] PROT_ERR_EN_CLR — Protection violation error enable clear. Write a 1 to clear the enable. Writing a 0 has no effect.
0x1018 TOP_CTRL_INTR_ENABLE 8-bit rw
  [7:0] EOI_VECTOR — EOI vector value. Write this with interrupt distribution value in the chip.
0x101C TOP_CTRL_INTR_ENABLE_CLEAR
  [31:0] FAULT_ADDR — Fault Address.
0x1020 TOP_CTRL_EOI 8-bit
  [6] FAULT_NS — Non-secure access.
  [5:0] FAULT_TYPE — Fault Type 10_0000 = Supervisor read fault - priv = 1 dir = 1 dtype != 1 01_0000 = Supervisor write fault - priv = 1 dir = 0 00_1000 = Supervisor execute fault - priv = 1 dir = 1 dtype = 1 00_0100 = User read fault - priv = 0 dir = 1 dtype = 1 00_0010 = User write fault - priv = 0 dir = 0 00_0001 = User execute fault - priv = 0 dir = 1 dtype = 1 00_0000 = No fault
0x1024 TOP_CTRL_FAULT_ADDRESS
  [31:20] FAULT_XID — XID.
  [19:8] FAULT_ROUTEID — Route ID.
  [7:0] FAULT_PRIVID — Privilege ID.
0x1028 TOP_CTRL_FAULT_TYPE_STATUS size not given wo
  [0] FAULT_CLR — Fault clear. Writing a 1 clears the current fault. Writing a 0 has no effect.
